# Global_Reg_PRM register map
Vendor: Texas Instruments
Peripheral module from a debugger description file (folder omap36xx).
Registers are 32-bit, access per field, reset values left out (the file's numbers can be read two ways) unless marked. A register's access mark holds for its fields unless they carry their own. Offsets are as the file gives them; lines under a group give offsets from that group; [hi:lo] are bit positions; {n}, {i} and the like mark numbered series; 'fields as' and 'values as' point back to an identical list; <NAME> marks a mode.

## Global_Reg_PRM
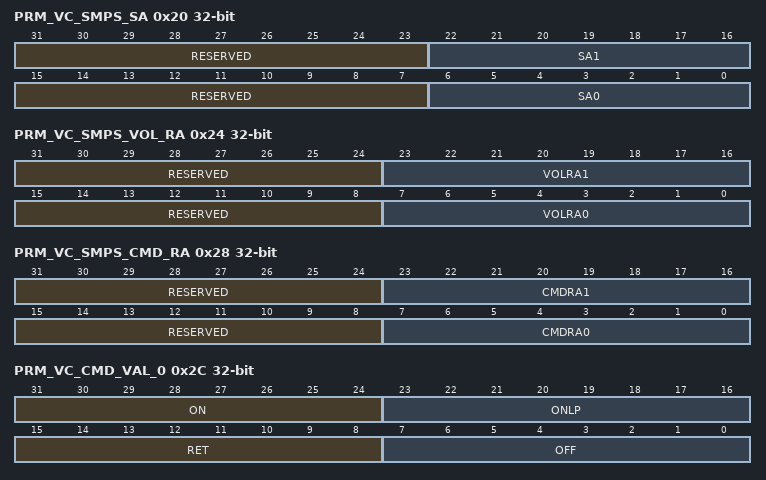
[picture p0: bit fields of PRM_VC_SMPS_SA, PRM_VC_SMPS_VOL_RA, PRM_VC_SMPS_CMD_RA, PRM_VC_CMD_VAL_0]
0x20 PRM_VC_SMPS_SA — This register allows the setting of the I2C slave address of the Power IC device.
  [31:23] RESERVED ro — Write 0s for future compatibility. Read is undefined.
  [22:16] SA1 rw — Set the IC slave address value for the second (if any) Power IC device.
  [15:7] RESERVED ro — Write 0s for future compatibility. Read is undefined.
  [6:0] SA0 rw — Set the IC slave address value for the first Power IC device.
0x24 PRM_VC_SMPS_VOL_RA — This register allows the setting of the voltage configuration register address for the VDD channels.
  [31:24] RESERVED ro — Write 0s for future compatibility. Read is undefined.
  [23:16] VOLRA1 rw — Set the voltage configuration register address value for the second VDD channel (VDD2).
  [15:8] RESERVED ro — Write 0s for future compatibility. Read is undefined.
  [7:0] VOLRA0 rw — Set the voltage configuration register address value for the first VDD channel (VDD1).
0x28 PRM_VC_SMPS_CMD_RA — This register allows the setting of the ON/Retention/OFF command configuration register address for the VDD channels. It is used if the Power IC device has different register addresses for voltage value and ON/Retention/OFF command.
  [31:24] RESERVED ro — Write 0s for future compatibility. Read is undefined.
  [23:16] CMDRA1 rw — Set the ON/ON-LP/Retention/OFF command configuration register address value for the second VDD channel (VDD2).
  [15:8] RESERVED ro — Write 0s for future compatibility. Read is undefined.
  [7:0] CMDRA0 rw — Set the ON/ON-LP/Retention/OFF command configuration register address value for the first VDD channel (VDD1).
0x2C PRM_VC_CMD_VAL_0 rw — This register allows the setting of the ON/Retention/OFF voltage level values for the first VDD channel.
  [31:24] ON — Set the ON voltage level value for the first VDD channel (VDD1).
  [23:16] ONLP — Set the ON-LP voltage level value for the first VDD channel (VDD1).
  [15:8] RET — Set the RET voltage level value for the first VDD channel (VDD1).
  [7:0] OFF — Set the OFF voltage level value for the first VDD channel (VDD1).
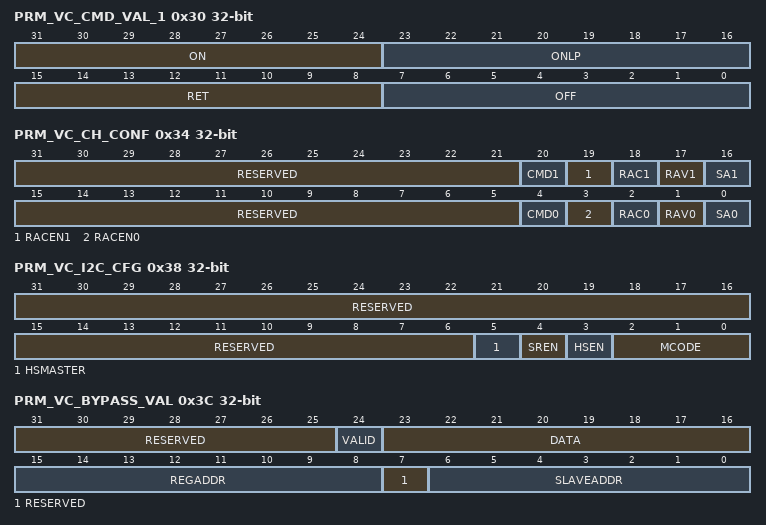
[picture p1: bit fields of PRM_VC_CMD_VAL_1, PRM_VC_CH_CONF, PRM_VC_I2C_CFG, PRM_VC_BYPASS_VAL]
0x30 PRM_VC_CMD_VAL_1 rw — This register allows the setting of the ON/Retention/OFF voltage level values for the second VDD channel. It is used if the second channel has different values than the first channel.
  [31:24] ON — Set the ON voltage level value for the second VDD channel (VDD2).
  [23:16] ONLP — Set the ON-LP voltage level value for the second VDD channel (VDD2).
  [15:8] RET — Set the RET voltage level value for the second VDD channel (VDD2).
  [7:0] OFF — Set the OFF voltage level value for the second VDD channel (VDD2).
0x34 PRM_VC_CH_CONF — This register allows the configuration pointers for both VDD channels.
  [31:21] RESERVED ro — Write 0s for future compatibility. Read is undefined.
  [20] CMD1 rw — Selects the ON/ON-LP/Retention/OFF voltage values for the second VDD channel (VDD2).
  [19] RACEN1 rw — Enable bit for usage of RAC1.
  [18] RAC1 rw — Set the ON/ON-LP/Retention/OFF command configuration register address pointer for the second VDD channel (VDD2).
  [17] RAV1 rw — Set the voltage configuration register address pointer for the second VDD channel (VDD2).
  [16] SA1 rw — Set the slave address pointer for the second VDD channel (VDD2).
  [15:5] RESERVED ro — Write 0s for future compatibility. Read is undefined.
  [4] CMD0 rw — Selects the ON/ON-LP/Retention/OFF voltage values for the first VDD channel (VDD1).
  [3] RACEN0 rw — Enable bit for usage of RAC0.
  [2] RAC0 rw — Set the ON/ON-LP/Retention/OFF command configuration register address pointer for the first VDD channel (VDD1).
  [1] RAV0 rw — Set the voltage configuration register address pointer for the first VDD channel (VDD1).
  [0] SA0 rw — Set the slave address pointer for the first VDD channel (VDD1).
0x38 PRM_VC_I2C_CFG — This register allows the configuration pointers for both VDD channels.
  [31:6] RESERVED ro — Write 0s for future compatibility. Read is undefined.
  [5] HSMASTER rw — Put the I2C pads in a low power mode in case of light load.
    0=Disables the I2C pads low power mode; 1=Enables the I2C pads low power mode
  [4] SREN rw — Enables the I2C repeated start operation mode.
    0=Disables the repeated start operation mode; 1=Enables the repeated start operation mode
  [3] HSEN rw — Enables I2C bus High Speed mode.
    0=Disables the I2C high speed mode; 1=Enables the I2C high speed mode
  [2:0] MCODE rw — Master code value for I2C High Speed preamble transmission.
0x3C PRM_VC_BYPASS_VAL rw — This register allows the programming of the Power IC device using the bypass interface.
  [31:25] RESERVED — Write 0s for future compatibility. Read is undefined.
  [24] VALID — This bit validates the bypass command. It is automatically cleared by HW either after getting the acknowledge back from the SMPS or if an error occured.
    0=The last command send has been acknowledged; 1=The Voltage Controller send the command to the I2C interface; 1=Pending command is being process
  [23:16] DATA — Data to send to the Power IC device.
  [15:8] REGADDR — Set the address of Power IC device register to configure.
  [7] RESERVED — Write 0s for future compatibility. Read is undefined.
  [6:0] SLAVEADDR — Set the I2C slave address value.
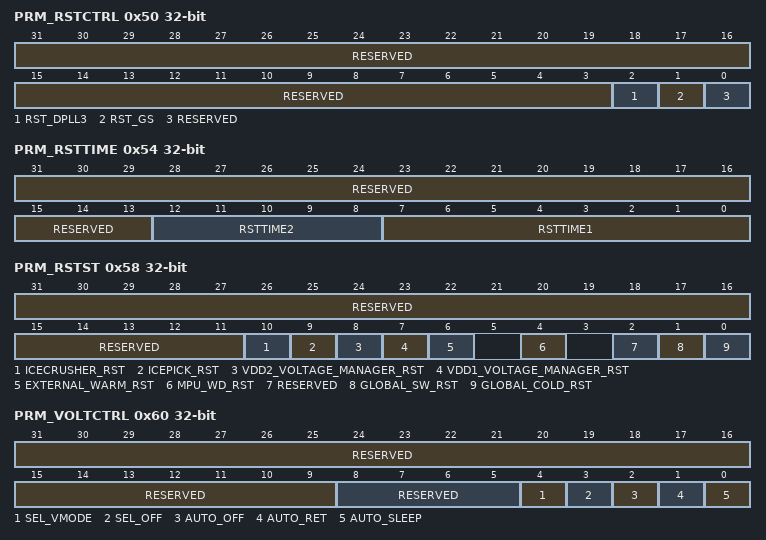
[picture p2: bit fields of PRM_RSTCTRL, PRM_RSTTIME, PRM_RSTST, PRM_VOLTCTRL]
0x50 PRM_RSTCTRL — Global software and DPLL3 reset control. This register is auto-cleared. Only write 1 is possible. A read returns 0 only.
  [31:3] RESERVED ro — Write 0s for future compatibility. Read returns 0.
  [2] RST_DPLL3 rw — DPLL3 software reset control. This bit is reset only upon a global cold source of reset.
    0=DPLL3 software reset is cleared; 1=Asserts the DPLL3 software reset and induces a global cold reset on the whole chip. The software must ensure the SDRAM is properly put in sef-refresh mode before applying this reset.
  [1] RST_GS rw — Global software reset control. This bit is reset upon any global source of reset (warm and cold).
    0=Global software reset is cleared; 1=Asserts a global software reset
  [0] RESERVED ro — Write 0s for future compatibility. Read returns 0.
0x54 PRM_RSTTIME — Reset duration control.
  [31:13] RESERVED ro — Write 0s for future compatibility. Read returns 0.
  [12:8] RSTTIME2 rw — (Power domain) reset duration 2(number of RM_ICLK clock cycles)
  [7:0] RSTTIME1 rw — (Global) reset duration 1(number of Func_32k.clk clock cycles)
0x58 PRM_RSTST — This register logs the global reset sources. Each bit is set upon release of the domain reset signal. Must be cleared by software.
  [31:11] RESERVED ro — Write 0s for future compatibility. Read returns 0.
  [10] ICECRUSHER_RST rw — IceCrusher reset event. This is a source of warm reset initiated by the emulation.
    0=ICECRUSHER_RST_0_r (No IceCrusher reset.); 0=ICECRUSHER_RST_0_w (Status bit unchanged); 1=ICECRUSHER_RST_1_r (IceCrusher reset occurred.); 1=ICECRUSHER_RST_1_w (Status bit is cleared to 0.)
  [9] ICEPICK_RST rw — IcePick reset event. This is a source of warm reset initiated by the emulation.
    0=ICEPICK_RST_0_r (No IcePick reset.); 0=ICEPICK_RST_0_w (Status bit unchanged); 1=ICEPICK_RST_1_r (IcePick reset occurred.); 1=ICEPICK_RST_1_w (Status bit is cleared to 0.)
  [8] VDD2_VOLTAGE_MANAGER_RST rw — VDD2 voltage manager reset event
    0=VDD2_VOLTAGE_MANAGER_RST_0_r (No VDD2 voltage manager reset.); 0=VDD2_VOLTAGE_MANAGER_RST_0_w (Status bit unchanged); 1=VDD2_VOLTAGE_MANAGER_RST_1_r (VDD2 voltage manager reset occurred.); 1=VDD2_VOLTAGE_MANAGER_RST_1_w (Status bit is cleared to 0.)
  [7] VDD1_VOLTAGE_MANAGER_RST rw — VDD1 voltage manager reset event
    0=VDD1_VOLTAGE_MANAGER_RST_0_r (No VDD1 voltage manager reset.); 0=VDD1_VOLTAGE_MANAGER_RST_0_w (Status bit unchanged); 1=VDD1_VOLTAGE_MANAGER_RST_1_r (VDD1 voltage manager reset occurred.); 1=VDD1_VOLTAGE_MANAGER_RST_1_w (Status bit is cleared to 0.)
  [6] EXTERNAL_WARM_RST rw — External warm reset event
    0=EXTERNAL_WARM_RST_0_r (No global warm reset.); 0=EXTERNAL_WARM_RST_0_w (Status bit unchanged); 1=EXTERNAL_WARM_RST_1_r (Global external warm reset occurred.); 1=EXTERNAL_WARM_RST_1_w (Status bit is cleared to 0.)
  [4] MPU_WD_RST rw — MPU watchdog reset event
    0=MPU_WD_RST_0_r (No MPU watchdog reset.); 0=MPU_WD_RST_0_w (Status bit unchanged); 1=MPU_WD_RST_1_r (MPU wachtdog reset occurred.); 1=MPU_WD_RST_1_w (Status bit is cleared to 0.)
  [2] RESERVED ro — Write 0s for future compatibility. Read returns 0.
  [1] GLOBAL_SW_RST rw — Global software reset event
    0=GLOBAL_SW_RST_0_r (No global software reset.); 0=GLOBAL_SW_RST_0_w (Status bit unchanged); 1=GLOBAL_SW_RST_1_r (Global software reset occurred.); 1=GLOBAL_SW_RST_1_w (Status bit is cleared to 0.)
  [0] GLOBAL_COLD_RST rw — Power-up (cold) reset event
    0=GLOBAL_COLD_RST_0_r (No power-on reset.); 0=GLOBAL_COLD_RST_0_w (Status bit unchanged); 1=GLOBAL_COLD_RST_1_r (Power-on reset occurred.); 1=GLOBAL_COLD_RST_1_w (Status bit is cleared to 0.)
0x60 PRM_VOLTCTRL — This register allows a direct control on the external power IC.
  [31:9] RESERVED ro — Write 0s for future compatibility. Read returns 0.
  [8:5] RESERVED ro — Write 0s for future compatibility. Read returns 0.
  [4] SEL_VMODE rw — This bit allows to select the mode used to control the Power IC (I2C or VMODE).
    0=The Power IC is controlled through theSR dedicatedI2C interface; 1=The Power IC is controlled through the VMODE interface
  [3] SEL_OFF rw — This bit allows to select the mode used to send the OFF command.
    0=The OFF command is send through the voltage controller I2C interface; 1=The signal SYS.OFF_MODE is asserted
  [2] AUTO_OFF rw — This bit allows to send an OFF command to the Power IC.
    0=The OFF command is not send; 1=The OFF command is automatically send when the voltage domain is in the appropriate standby mode
  [1] AUTO_RET rw — This bit allows to send a RETENTION command to the Power IC through the voltage controller I2C interface.
    0=The RETENTION command is not send; 1=The RETENTION command is automatically send when the voltage domain is in the appropriate standby mode
  [0] AUTO_SLEEP rw — This bit allows to send a SLEEP command to the Power IC through the voltage controller I2C interface.
    0=The SLEEP command is not send; 1=The SLEEP command is automatically send when the voltage domain is in the appropriate standby mode
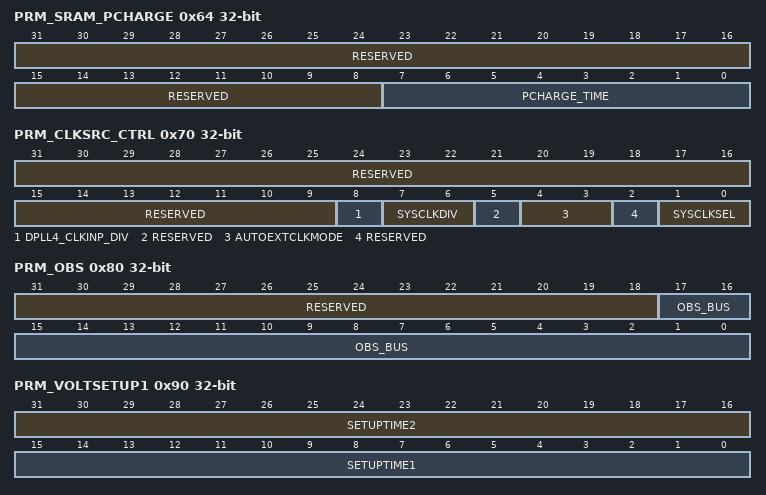
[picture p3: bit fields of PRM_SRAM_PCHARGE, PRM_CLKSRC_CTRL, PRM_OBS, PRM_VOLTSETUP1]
0x64 PRM_SRAM_PCHARGE — This register allows setting the pre-charge time of the SRAM.
  [31:8] RESERVED ro — Write 0s for future compatibility. Read returns 0.
  [7:0] PCHARGE_TIME rw — Number of system clock cycles for the SRAM pre-charge duration.
0x70 PRM_CLKSRC_CTRL — This register provides control over the device source clock.
  [31:9] RESERVED ro — Write 0s for future compatibility. Read returns 0.
  [8] DPLL4_CLKINP_DIV rw — This field controls the divider of the DPLL4 reference clock.
    0=The DPLL4 reference clock is the system clock divided by 1; 1=The DPLL4 reference clock is the system clock divided by 6.5
  [7:6] SYSCLKDIV rw — This field controls the system clock input divider
    1=Syst_clk is external clock / 1; 2=Syst_clk is external clock / 2
  [5] RESERVED ro — Write 0s for future compatibility. Read returns 0.
  [4:3] AUTOEXTCLKMODE rw — This field allows to control the external clock request (CLKREQ) and the oscillator
    0=CLKREQ is kept asserted or the oscillator is always active (in master mode); 1=CLKREQ is de-asserted or the oscillator is put in power-down mode (in master mode) when all the voltages domains are SLEEP, RETENTION or OFF states; 2=CLKREQ is de-asserted or the oscillator is put in power-down mode (in master mode) when all the voltages domains are RETENTION or OFF states; 3=CLKREQ is de-asserted or the oscillator is put in power-down mode (in master mode) only when all the voltage domains are in OFF states
  [2] RESERVED ro — Write 0s for future compatibility. Read returns 0.
  [1:0] SYSCLKSEL ro — This field reflects the mode of the ocillator. It is automatically set accordingly to the external tied-off configuration and its value is unsignificant before the release of the power-on reset.
    0=Bypass mode: the system clock is issued from an external square clock source; 1=Oscillator mode: the system clock is issued from an external quartz; 3=Unknow state (not know before release of the power-on reset)
0x80 PRM_OBS ro — This register logs the observable signals (18 bits). This register is intended to be read through the debugger interface when the device is in OFF mode.
  [31:18] RESERVED — Read is undefined.
  [17:0] OBS_BUS — Indicates the current value on the observable bus.
0x90 PRM_VOLTSETUP1 rw — This register allows setting the setup time of the VDD1 and VDD2 regulators. This register is used when exiting OFF/RET/SLEEP mode (or enters OFF/RET/SLEEP mode) and when device manages the sequencing of the voltages regulation steps.
  [31:16] SETUPTIME2 — The value, in number of cycles of SYS_CLK, determines the setup duration of VDD2 regulator. The setup duration is computed as = 8 x number of cycles of SYS_CLK set in the register bit field.
  [15:0] SETUPTIME1 — The value, in number of cycles of SYS_CLK, determines the setup duration of VDD1 regulator. The setup duration is computed as = 8 x number of cycles of SYS_CLK set in the register bit field.
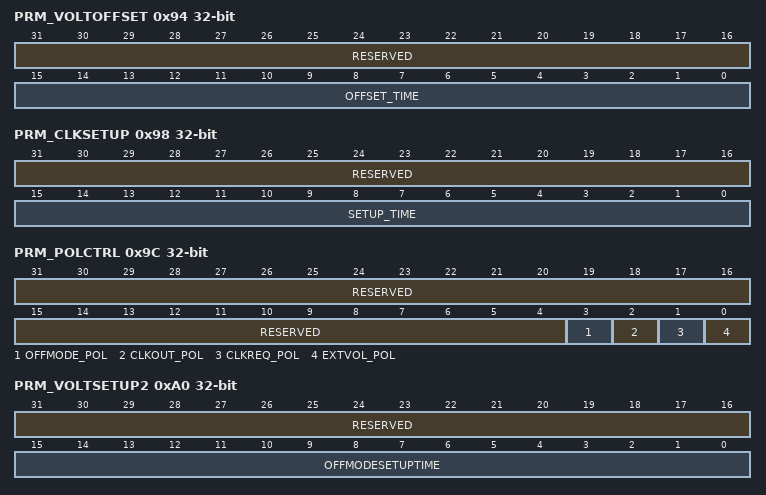
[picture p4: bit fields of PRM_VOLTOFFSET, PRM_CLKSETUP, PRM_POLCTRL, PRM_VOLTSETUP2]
0x94 PRM_VOLTOFFSET — This register allows controlling the sys_offmode signal upon wake-up from OFF mode when the OFF sequence is supervised by the Power IC. This register allows setting the offset-time to de-assert sys_offmode when exiting the OFF mode.
  [31:16] RESERVED ro — Write 0s for future compatibility. Read returns 0.
  [15:0] OFFSET_TIME rw — Number of 32kHz clock cycles for the OFF mode offset time
0x98 PRM_CLKSETUP — This register allows setting the setup time of the oscillator system clock (sys_clk), based on number of 32 kHz clock cycles.
  [31:16] RESERVED ro — Write 0s for future compatibility. Read returns 0.
  [15:0] SETUP_TIME rw — Number of 32kHz clock cycles for the SETUP duration
0x9C PRM_POLCTRL — This register allows setting the polarity of device outputs control signals.
  [31:4] RESERVED ro — Write 0s for future compatibility. Read returns 0.
  [3] OFFMODE_POL rw — Controls the polarity of the sys_offmode signal
    0=sys_offmode is active low; 1=sys_offmode is active high
  [2] CLKOUT_POL rw — Controls the external output clock polarity when disabled
    0=sys_clkout is gated low when inactive; 1=sys_clkout is gated high when inactive
  [1] CLKREQ_POL rw — Controls the polarity of the sys_clkreq signal
    0=sys_clkreq is active low; 1=sys_clkreq is active high
  [0] EXTVOL_POL rw — Controls the polarity of sys_vmode signal
    0=sys_vmode signal is active low; 1=sys_vmode signal is active high
0xA0 PRM_VOLTSETUP2 — This register allows setting the overall setup time of VDD1 and VDD2 regulators. This register is used when exiting OFF mode and when the Power IC manages the sequencing of the voltages regulation steps.
  [31:16] RESERVED ro — Write 0s for future compatibility. Read returns 0.
  [15:0] OFFMODESETUPTIME rw — Number of 32kHz clock cycles for the overall setup time of VDD1 and VDD2 regulators.
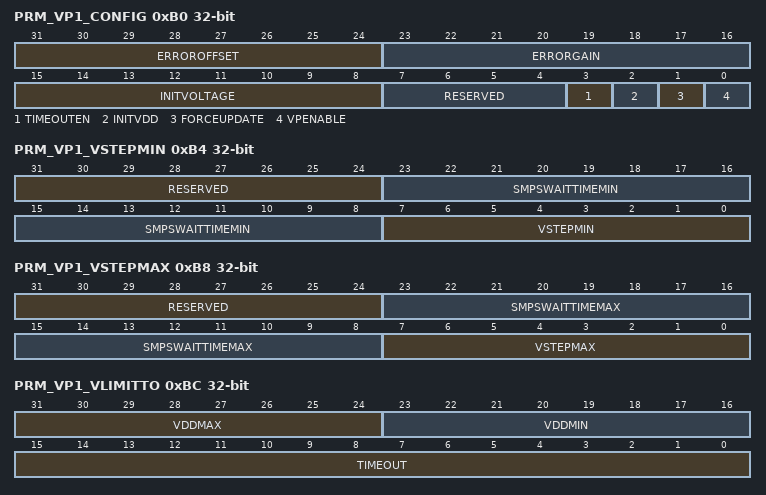
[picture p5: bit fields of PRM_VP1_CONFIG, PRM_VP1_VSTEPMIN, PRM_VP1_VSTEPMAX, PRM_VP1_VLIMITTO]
0xB0 PRM_VP1_CONFIG — This register allows the configuration of the Voltage Processor 1 (VDD1).
  [31:24] ERROROFFSET rw — Offset value in the Error to Voltage converter (two's complement number).
  [23:16] ERRORGAIN rw — Gain value in the Error to Voltage converter (two's complement number).
  [15:8] INITVOLTAGE rw — Set the initial voltage level of the SMPS. It must be reconfigured before SmartReflex is enabled around a new OPP.
  [7:4] RESERVED ro — Write 0s for future compatibility. Read is undefined.
  [3] TIMEOUTEN rw — Enable or disable the timeout capability of the Voltage Controller State Machine.
    0=Timeout is disabled. Loop will wait indefinitely.; 1=Timeout will occur when TIMEOUT cycles have elapsed
  [2] INITVDD rw — Initializes the voltage in the Voltage Processor.
    0=Reset the initialization bit; 1=The positive edge of InitVdd triggers a write of the value in the InitVoltage into the Voltage Processor
  [1] FORCEUPDATE rw — Forces an update of the SMPS.
    0=Reset the force bit; 1=The positive edge of ForceUpdate triggers an update of the voltage to the SMPS
  [0] VPENABLE rw — Enables or disables the Voltage Processor.
    0=Disables the Voltage Processor; 1=Enables the Voltage Processor
0xB4 PRM_VP1_VSTEPMIN — This register allows the programming of the minimum voltage step and waiting time of the Voltage Processor 1 (VDD1).
  [31:24] RESERVED ro — Write 0s for future compatibility. Read is undefined.
  [23:8] SMPSWAITTIMEMIN rw — Slew rate for negative voltage step (in number of cycles per step).
  [7:0] VSTEPMIN rw — Minimum voltage step
0xB8 PRM_VP1_VSTEPMAX — This register allows the programming of the maximum voltage step and waiting time of the Voltage Processor 1 (VDD1).
  [31:24] RESERVED ro — Write 0s for future compatibility. Read is undefined.
  [23:8] SMPSWAITTIMEMAX rw — Slew rate for positive voltage step (in number of cycles per step).
  [7:0] VSTEPMAX rw — Maximum voltage step
0xBC PRM_VP1_VLIMITTO rw — This register allows the configuration of the voltage limits and timeout values of the Voltage Processor 1 (VDD1).
  [31:24] VDDMAX — Defines the maximum voltage supply level.
  [23:16] VDDMIN — Defines the minimum voltage supply level.
  [15:0] TIMEOUT — Defines Voltage Controller maximum wait time for responses.
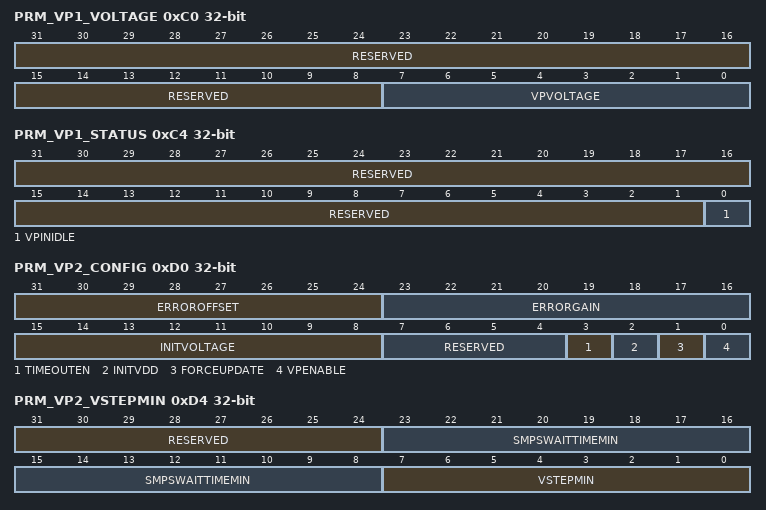
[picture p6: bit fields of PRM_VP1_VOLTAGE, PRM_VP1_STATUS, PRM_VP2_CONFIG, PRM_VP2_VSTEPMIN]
0xC0 PRM_VP1_VOLTAGE ro — This register indicates the current value of the SMPS voltage for the Voltage Processor 1 (VDD1).
  [31:8] RESERVED — Read is undefined.
  [7:0] VPVOLTAGE — Indicates the current SMPS programmed voltage.
0xC4 PRM_VP1_STATUS ro — This register reflects the idle state of the Voltage Processor 1 (VDD1). This register is read only and automatically updated.
  [31:1] RESERVED — Write 0s for future compatibility. Read is undefined.
  [0] VPINIDLE — Voltage Processor 1 idle status.
    0=The Voltage Processor 1 is processing; 1=The Voltage Processor 1 is in idle state
0xD0 PRM_VP2_CONFIG — This register allows the configuration of the Voltage Processor 2 (VDD2).
  fields as PRM_VP1_CONFIG
0xD4 PRM_VP2_VSTEPMIN — This register allows the programming of the minimum voltage step and waiting time of the Voltage Processor 2 (VDD2).
  fields as PRM_VP1_VSTEPMIN
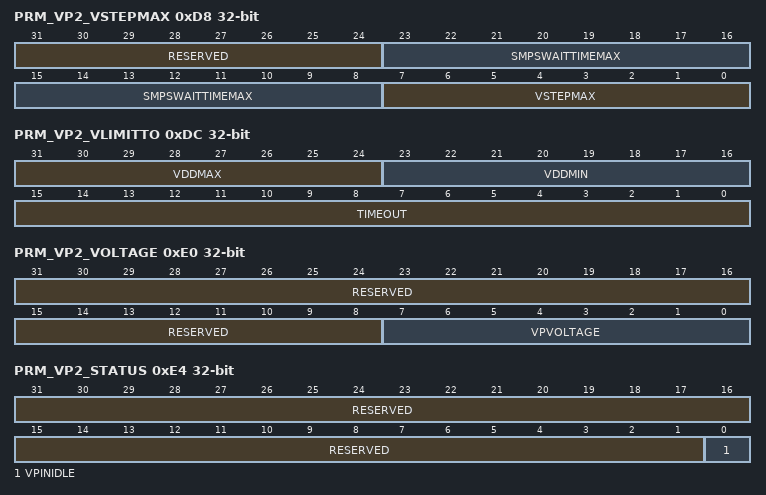
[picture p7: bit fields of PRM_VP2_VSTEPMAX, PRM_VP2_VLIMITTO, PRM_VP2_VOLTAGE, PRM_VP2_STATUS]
0xD8 PRM_VP2_VSTEPMAX — This register allows the programming of the maximum voltage step and waiting time of the Voltage Processor 2 (VDD2).
  fields as PRM_VP1_VSTEPMAX
0xDC PRM_VP2_VLIMITTO rw — This register allows the configuration of the voltage limits and timeout values of the Voltage Processor 2 (VDD2).
  fields as PRM_VP1_VLIMITTO
0xE0 PRM_VP2_VOLTAGE ro — This register indicates the current value of the SMPS voltage for the Voltage Processor 2 (VDD2).
  fields as PRM_VP1_VOLTAGE
0xE4 PRM_VP2_STATUS ro — This register reflects the idle state of the Voltage Processor 2 (VDD2). This register is read only and automatically updated.
  [31:1] RESERVED — Write 0s for future compatibility. Read is undefined.
  [0] VPINIDLE — Voltage Processor 2 idle status.
    0=The Voltage Processor 2 is processing; 1=The Voltage Processor 2 is in idle state
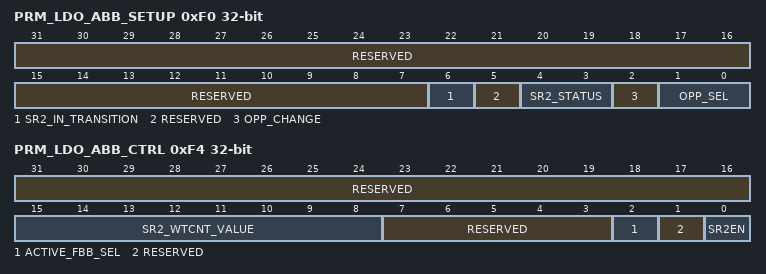
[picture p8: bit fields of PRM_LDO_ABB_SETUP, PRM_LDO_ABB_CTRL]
0xF0 PRM_LDO_ABB_SETUP — This register allows the configuration of the ABB LDO (VDD1).
  [31:7] RESERVED ro — Write 0s for future compatibility. Read is undefined.
  [6] SR2_IN_TRANSITION ro — Indicates if the ABB LDO is transitioning into a new mode of operation.
    0=The ABB LDO is not transition and the SR2_STATUS bits field is stable; 1=The ABB LDO is transitioning in a new mode and the SR2_STATUS bits field is not stable
  [5] RESERVED ro — Write 0s for future compatibility. Read is undefined.
  [4:3] SR2_STATUS ro — Indicates the current mode of operation of the ABB LDO.
    0=The ABB LDO is in bypass mode; 2=The ABB LDO is in FBB mode
  [2] OPP_CHANGE rw — The ABB LDO controller samples OPP_SEL bits field and ACTIVE_RRB_SEL and ACTIVE_FBB_SEL bit fields upon rising edge of this bit. It is automatically cleared by the PRCM HW upon completion of the ABB LDO transition.
    0=No ABB LDO transition on going or ABB LDO transition has been completed; 1=Request the ABB LDO to transition
  [1:0] OPP_SEL rw — Selects the OPP at which the voltage VDD1 is operating (or is going to switch to).
    0=Default is nominal OPP; 1=Fast OPP; 2=Nominal OPP; 3=Slow OPP
0xF4 PRM_LDO_ABB_CTRL — This register allows the configuration of the ABB LDO (VDD1).
  [31:16] RESERVED ro — Write 0s for future compatibility. Read is undefined.
  [15:8] SR2_WTCNT_VALUE rw — This value times 8 is used to set the ABB LDO settling time to switch from the bypass mode to a Body-Bias mode.
    0=No wait-cycles are inserted
  [7:3] RESERVED ro — Write 0s for future compatibility. Read is undefined.
  [2] ACTIVE_FBB_SEL rw — Defines the ABB LDO mode when the voltage (VDD1) is in fast OPP (OPP1G).
    0=ABB LDO will operate in bypass mode; 1=ABB LDO will operate in FBB mode
  [1] RESERVED ro — Write 0s for future compatibility. Read is undefined.
  [0] SR2EN rw — Enables the ABB LDO.
    0=ABB LDO is in bypass mode; 1=ABB LDO will operate in FBB mode or bypass mode accordingly to the other SW settings and HW events
